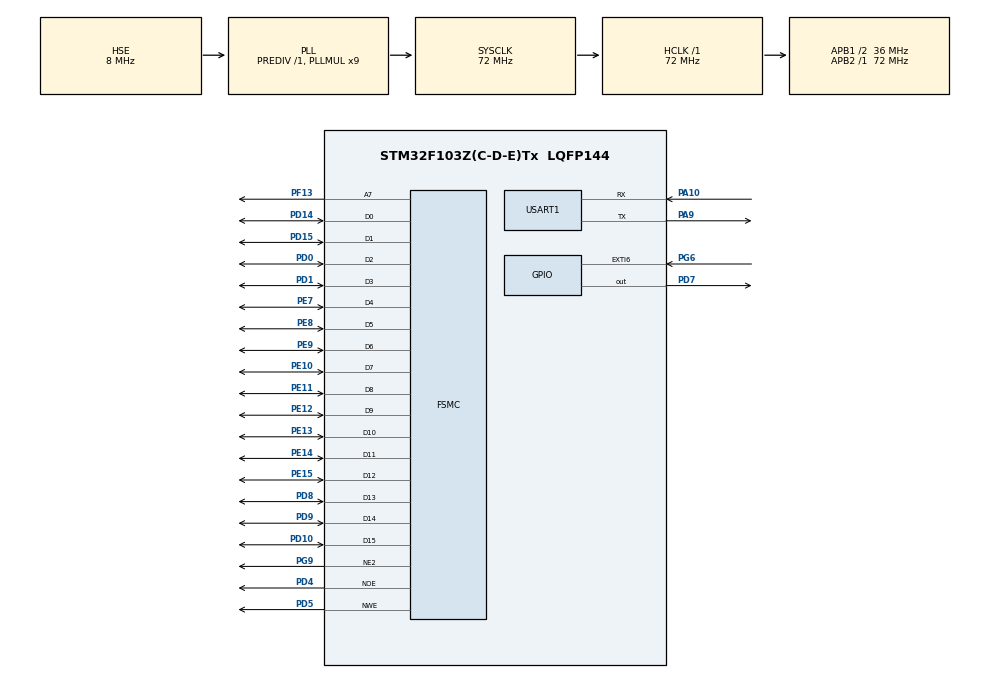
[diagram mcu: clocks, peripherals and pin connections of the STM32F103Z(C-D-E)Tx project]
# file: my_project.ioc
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FSMC.AddressSetupTime2=0
FSMC.DataSetupTime2=3
FSMC.ExtendedMode2=FSMC_EXTENDED_MODE_DISABLE
Mcu.Family=STM32F1
Mcu.Name=STM32F103Z(C-D-E)Tx
Mcu.Package=LQFP144
NVIC.EXTI9_5_IRQn=true\:1\:1\:true\:true\:true\:1
NVIC.PriorityGroup=NVIC_PRIORITYGROUP_2
NVIC.TIM1_UP_IRQn=true\:2\:2\:true\:true\:true\:2
NVIC.TIM7_IRQn=true\:1\:1\:true\:true\:true\:4
NVIC.USART1_IRQn=true\:2\:1\:true\:true\:true\:3
OSC_IN.Mode=HSE-External-Oscillator
OSC_IN.Signal=RCC_OSC_IN
OSC_OUT.Mode=HSE-External-Oscillator
OSC_OUT.Signal=RCC_OSC_OUT
PA10.Mode=Asynchronous
PA10.Signal=USART1_RX
PA9.Mode=Asynchronous
PA9.Signal=USART1_TX
PD0.Signal=FSMC_D2_DA2
PD1.Signal=FSMC_D3_DA3
PD10.Signal=FSMC_D15_DA15
PD14.Signal=FSMC_D0_DA0
PD15.Signal=FSMC_D1_DA1
PD4.Signal=FSMC_NOE
PD5.Signal=FSMC_NWE
PD7.GPIO_Speed=GPIO_SPEED_FREQ_MEDIUM
PD7.Signal=GPIO_Output
PD8.Signal=FSMC_D13_DA13
PD9.Signal=FSMC_D14_DA14
PE10.Signal=FSMC_D7_DA7
PE11.Signal=FSMC_D8_DA8
PE12.Signal=FSMC_D9_DA9
PE13.Signal=FSMC_D10_DA10
PE14.Signal=FSMC_D11_DA11
PE15.Signal=FSMC_D12_DA12
PE7.Signal=FSMC_D4_DA4
PE8.Signal=FSMC_D5_DA5
PE9.Signal=FSMC_D6_DA6
PF13.Signal=FSMC_A7
PG6.GPIO_ModeDefaultEXTI=GPIO_MODE_IT_FALLING
PG6.GPIO_PuPd=GPIO_PULLUP
PG6.Signal=GPXTI6
PG9.Mode=NorPsramChipSelect2_2
PG9.Signal=FSMC_NE2
ProjectManager.HeapSize=0x200
ProjectManager.StackSize=0x400
ProjectManager.TargetToolchain=MDK-ARM V5
RCC.AHBFreq_Value=72000000
RCC.APB1CLKDivider=RCC_HCLK_DIV2
RCC.APB1Freq_Value=36000000
RCC.APB1TimFreq_Value=72000000
RCC.APB2Freq_Value=72000000
RCC.APB2TimFreq_Value=72000000
RCC.HCLKFreq_Value=72000000
RCC.PLLMUL=RCC_PLL_MUL9
RCC.PLLSourceVirtual=RCC_PLLSOURCE_HSE
RCC.SYSCLKFreq_VALUE=72000000
RCC.SYSCLKSource=RCC_SYSCLKSOURCE_PLLCLK
RCC.USBFreq_Value=72000000
SH.FSMC_A7.0=FSMC_A7,A7_2
SH.FSMC_D0_DA0.0=FSMC_D0,16b-d2
SH.FSMC_D10_DA10.0=FSMC_D10,16b-d2
SH.FSMC_D11_DA11.0=FSMC_D11,16b-d2
SH.FSMC_D12_DA12.0=FSMC_D12,16b-d2
SH.FSMC_D13_DA13.0=FSMC_D13,16b-d2
SH.FSMC_D14_DA14.0=FSMC_D14,16b-d2
SH.FSMC_D15_DA15.0=FSMC_D15,16b-d2
SH.FSMC_D1_DA1.0=FSMC_D1,16b-d2
SH.FSMC_D2_DA2.0=FSMC_D2,16b-d2
SH.FSMC_D3_DA3.0=FSMC_D3,16b-d2
SH.FSMC_D4_DA4.0=FSMC_D4,16b-d2
SH.FSMC_D5_DA5.0=FSMC_D5,16b-d2
SH.FSMC_D6_DA6.0=FSMC_D6,16b-d2
SH.FSMC_D7_DA7.0=FSMC_D7,16b-d2
SH.FSMC_D8_DA8.0=FSMC_D8,16b-d2
SH.FSMC_D9_DA9.0=FSMC_D9,16b-d2
SH.FSMC_NOE.0=FSMC_NOE,Lcd2
SH.FSMC_NWE.0=FSMC_NWE,Lcd2
TIM1.Period=9
TIM1.Prescaler=7199
TIM7.Period=199
TIM7.Prescaler=7199
USART1.VirtualMode=VM_ASYNC
VP_SYS_VS_ND.Mode=No_Debug
VP_TIM1_VS_ClockSourceINT.Mode=Internal
VP_TIM7_VS_ClockSourceINT.Mode=Enable_Timer
board=my_project

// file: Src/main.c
/**
  ******************************************************************************
  * File Name          : main.c
  * Description        : Main program body
  ******************************************************************************
  ** This notice applies to any and all portions of this file
  * that are not between comment pairs USER CODE BEGIN and
  * USER CODE END. Other portions of this file, whether
  * inserted by the user or by software development tools
  * are owned by their respective copyright owners.
  *
  * COPYRIGHT(c) 2018 STMicroelectronics
  *
  * Redistribution and use in source and binary forms, with or without modification,
  * are permitted provided that the following conditions are met:
  *   1. Redistributions of source code must retain the above copyright notice,
  *      this list of conditions and the following disclaimer.
  *   2. Redistributions in binary form must reproduce the above copyright notice,
  *      this list of conditions and the following disclaimer in the documentation
  *      and/or other materials provided with the distribution.
  *   3. Neither the name of STMicroelectronics nor the names of its contributors
  *      may be used to endorse or promote products derived from this software
  *      without specific prior written permission.
  *
  * THIS SOFTWARE IS PROVIDED BY THE COPYRIGHT HOLDERS AND CONTRIBUTORS "AS IS"
  * AND ANY EXPRESS OR IMPLIED WARRANTIES, INCLUDING, BUT NOT LIMITED TO, THE
  * IMPLIED WARRANTIES OF MERCHANTABILITY AND FITNESS FOR A PARTICULAR PURPOSE ARE
  * DISCLAIMED. IN NO EVENT SHALL THE COPYRIGHT HOLDER OR CONTRIBUTORS BE LIABLE
  * FOR ANY DIRECT, INDIRECT, INCIDENTAL, SPECIAL, EXEMPLARY, OR CONSEQUENTIAL
  * DAMAGES (INCLUDING, BUT NOT LIMITED TO, PROCUREMENT OF SUBSTITUTE GOODS OR
  * SERVICES; LOSS OF USE, DATA, OR PROFITS; OR BUSINESS INTERRUPTION) HOWEVER
  * CAUSED AND ON ANY THEORY OF LIABILITY, WHETHER IN CONTRACT, STRICT LIABILITY,
  * OR TORT (INCLUDING NEGLIGENCE OR OTHERWISE) ARISING IN ANY WAY OUT OF THE USE
  * OF THIS SOFTWARE, EVEN IF ADVISED OF THE POSSIBILITY OF SUCH DAMAGE.
  *
  ******************************************************************************
  */
#include "main.h"
#include "stm32f1xx_hal.h"
#include "tim.h"
#include "usart.h"
#include "gpio.h"
#include "fsmc.h"

/* USER CODE BEGIN Includes */
#include "my_main.h"
#include "lwip_demo.h"
/* USER CODE END Includes */

/* USER CODE BEGIN PV */
/* Private variables ---------------------------------------------------------*/

/* USER CODE END PV */

void SystemClock_Config(void);
static void MX_NVIC_Init(void);

/* USER CODE BEGIN PFP */
/* Private function prototypes -----------------------------------------------*/

/* USER CODE END PFP */

int main(void)
{

  /* MCU Configuration----------------------------------------------------------*/

  /* Reset of all peripherals, Initializes the Flash interface and the Systick. */
  HAL_Init();

  /* Configure the system clock */
  SystemClock_Config();

  /* Initialize all configured peripherals */
  MX_GPIO_Init();
  MX_TIM1_Init();
  MX_USART1_UART_Init();
  MX_FSMC_Init();
  MX_TIM7_Init();

  /* Initialize interrupts */
  MX_NVIC_Init();

  /* USER CODE BEGIN 2 */
	delay_init();
	HAL_TIM_Base_Start_IT(&htim1);
	HAL_TIM_Base_Start_IT(&htim7);
	__HAL_UART_ENABLE(&huart1);
	HAL_UART_Receive_IT(&huart1,get_recbf_adr(&G_USART_deliver),1);
  /* USER CODE END 2 */

  /* Infinite loop */
  while (1)
  {

  /* USER CODE BEGIN 3 */
	/*lwip process*/
	lwip_demo(0);
  }
  /* USER CODE END 3 */

}

/** System Clock Configuration
*/
void SystemClock_Config(void)
{

  RCC_OscInitTypeDef RCC_OscInitStruct;
  RCC_ClkInitTypeDef RCC_ClkInitStruct;

    /**Initializes the CPU, AHB and APB busses clocks
    */
  RCC_OscInitStruct.OscillatorType = RCC_OSCILLATORTYPE_HSE;
  RCC_OscInitStruct.HSEState = RCC_HSE_ON;
  RCC_OscInitStruct.HSEPredivValue = RCC_HSE_PREDIV_DIV1;
  RCC_OscInitStruct.HSIState = RCC_HSI_ON;
  RCC_OscInitStruct.PLL.PLLState = RCC_PLL_ON;
  RCC_OscInitStruct.PLL.PLLSource = RCC_PLLSOURCE_HSE;
  RCC_OscInitStruct.PLL.PLLMUL = RCC_PLL_MUL9;
  if (HAL_RCC_OscConfig(&RCC_OscInitStruct) != HAL_OK)
  {
    _Error_Handler(__FILE__, __LINE__);
  }

    /**Initializes the CPU, AHB and APB busses clocks
    */
  RCC_ClkInitStruct.ClockType = RCC_CLOCKTYPE_HCLK|RCC_CLOCKTYPE_SYSCLK
                              |RCC_CLOCKTYPE_PCLK1|RCC_CLOCKTYPE_PCLK2;
  RCC_ClkInitStruct.SYSCLKSource = RCC_SYSCLKSOURCE_PLLCLK;
  RCC_ClkInitStruct.AHBCLKDivider = RCC_SYSCLK_DIV1;
  RCC_ClkInitStruct.APB1CLKDivider = RCC_HCLK_DIV2;
  RCC_ClkInitStruct.APB2CLKDivider = RCC_HCLK_DIV1;

  if (HAL_RCC_ClockConfig(&RCC_ClkInitStruct, FLASH_LATENCY_2) != HAL_OK)
  {
    _Error_Handler(__FILE__, __LINE__);
  }

    /**Configure the Systick interrupt time
    */
  HAL_SYSTICK_Config(HAL_RCC_GetHCLKFreq()/1000);

    /**Configure the Systick
    */
  HAL_SYSTICK_CLKSourceConfig(SYSTICK_CLKSOURCE_HCLK);

  /* SysTick_IRQn interrupt configuration */
  HAL_NVIC_SetPriority(SysTick_IRQn, 0, 0);
}

/** NVIC Configuration
*/
static void MX_NVIC_Init(void)
{
  /* EXTI9_5_IRQn interrupt configuration */
  HAL_NVIC_SetPriority(EXTI9_5_IRQn, 1, 1);
  HAL_NVIC_EnableIRQ(EXTI9_5_IRQn);
  /* TIM1_UP_IRQn interrupt configuration */
  HAL_NVIC_SetPriority(TIM1_UP_IRQn, 2, 2);
  HAL_NVIC_EnableIRQ(TIM1_UP_IRQn);
  /* USART1_IRQn interrupt configuration */
  HAL_NVIC_SetPriority(USART1_IRQn, 2, 1);
  HAL_NVIC_EnableIRQ(USART1_IRQn);
  /* TIM7_IRQn interrupt configuration */
  HAL_NVIC_SetPriority(TIM7_IRQn, 1, 1);
  HAL_NVIC_EnableIRQ(TIM7_IRQn);
}

void _Error_Handler(char * file, int line)
{
  while(1)
  {
  }
}

/************************ (C) COPYRIGHT STMicroelectronics *****END OF FILE****/
